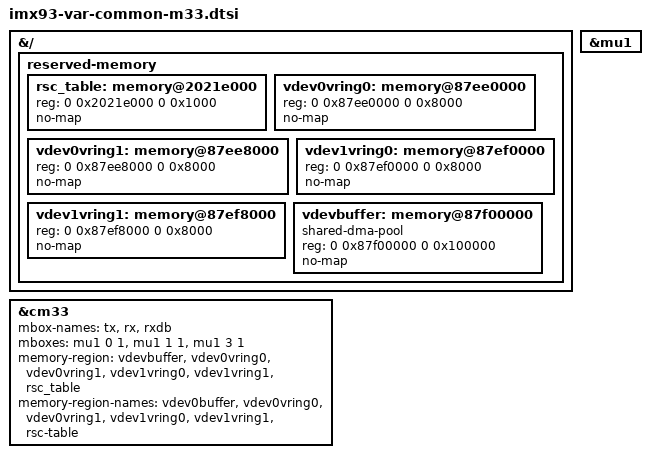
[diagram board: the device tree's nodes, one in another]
// SPDX-License-Identifier: (GPL-2.0+ OR MIT)
/*
 * Common Cortex-M33 configuration for Variscite i.MX93 modules
 *
 * Copyright (C) 2026 Variscite Ltd. - https://www.variscite.com/
 *
 */

&{/} {
	#address-cells = <2>;
	#size-cells = <2>;

	reserved-memory {
		#address-cells = <2>;
		#size-cells = <2>;
		ranges;

		rsc_table: memory@2021e000 {
			reg = <0 0x2021e000 0 0x1000>;
			no-map;
		};

		vdev0vring0: memory@87ee0000 {
			reg = <0 0x87ee0000 0 0x8000>;
			no-map;
		};

		vdev0vring1: memory@87ee8000 {
			reg = <0 0x87ee8000 0 0x8000>;
			no-map;
		};

		vdev1vring0: memory@87ef0000 {
			reg = <0 0x87ef0000 0 0x8000>;
			no-map;
		};

		vdev1vring1: memory@87ef8000 {
			reg = <0 0x87ef8000 0 0x8000>;
			no-map;
		};

		vdevbuffer: memory@87f00000 {
			compatible = "shared-dma-pool";
			reg = <0 0x87f00000 0 0x100000>;
			no-map;
		};
	};
};

&cm33 {
	mbox-names = "tx", "rx", "rxdb";
	mboxes = <&mu1 0 1
		  &mu1 1 1
		  &mu1 3 1>;
	memory-region = <&vdevbuffer>, <&vdev0vring0>, <&vdev0vring1>,
			<&vdev1vring0>, <&vdev1vring1>, <&rsc_table>;
	memory-region-names = "vdev0buffer", "vdev0vring0", "vdev0vring1",
			      "vdev1vring0", "vdev1vring1", "rsc-table";
	status = "okay";
};

&mu1 {
	status = "okay";
};
